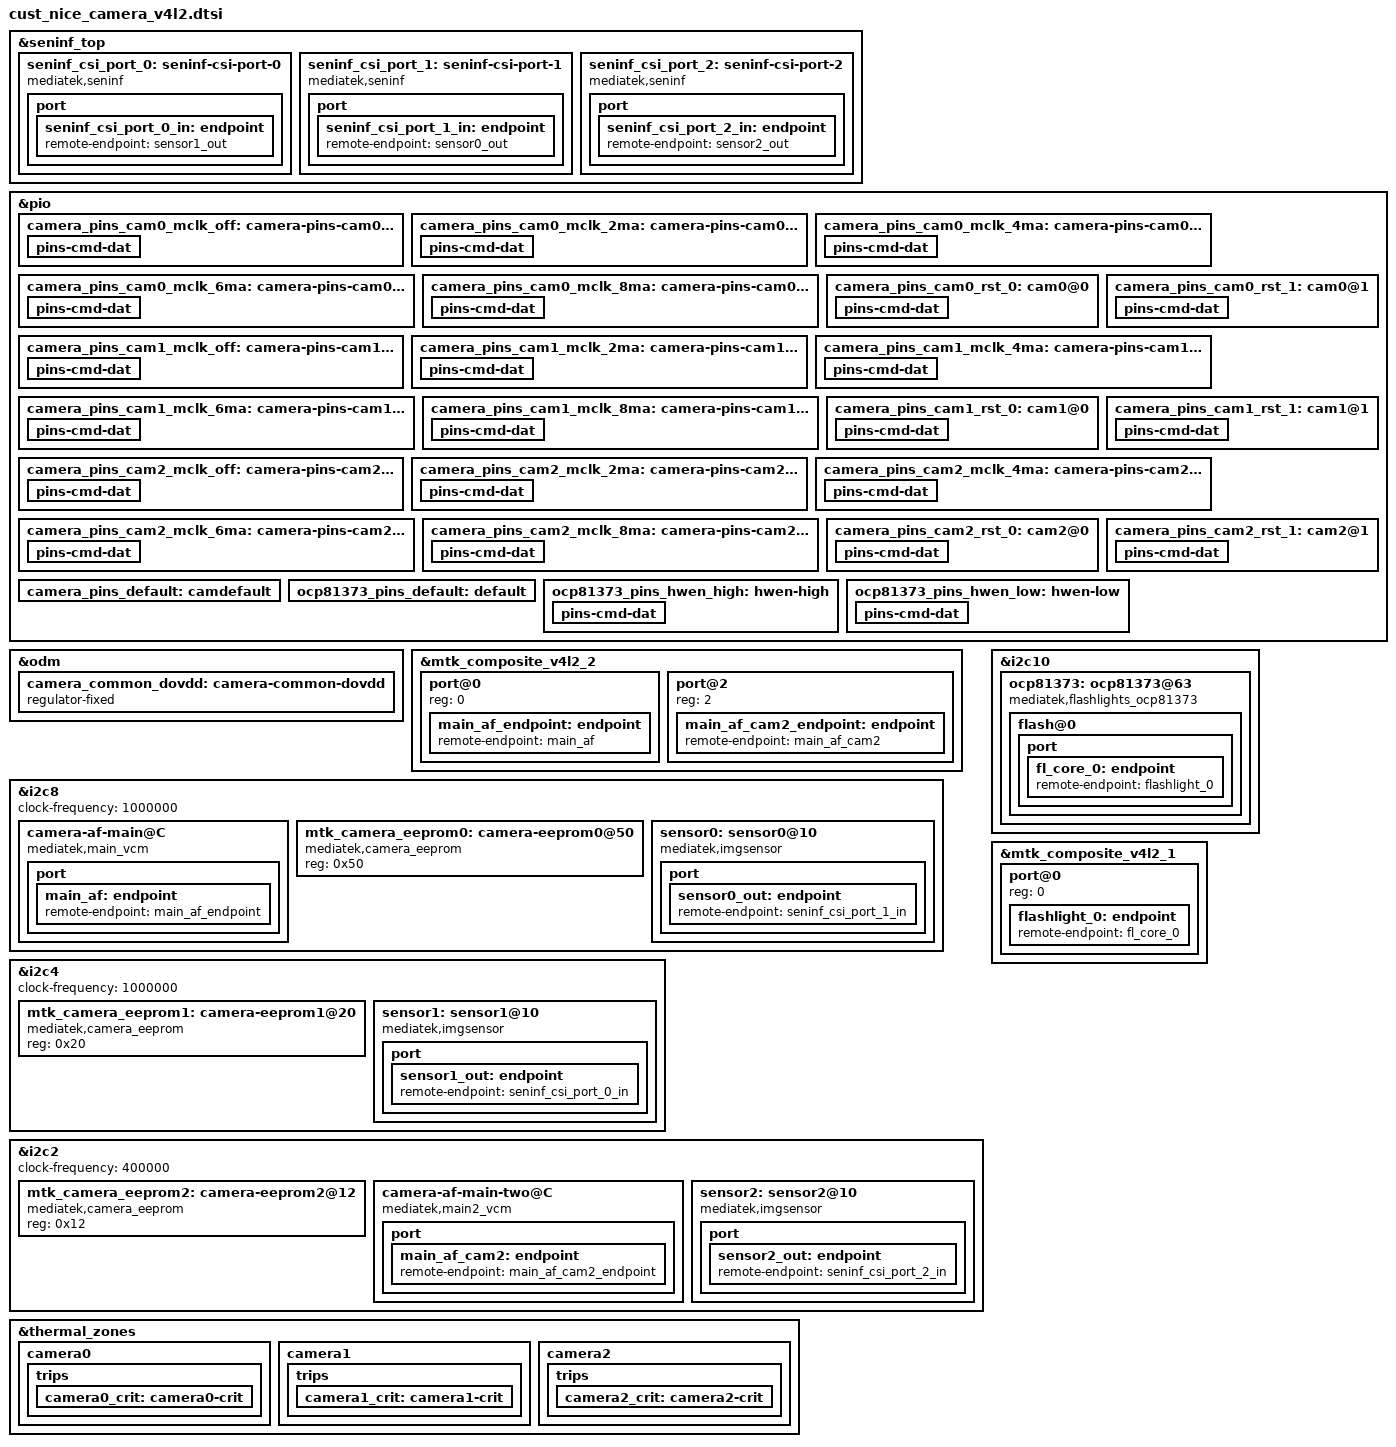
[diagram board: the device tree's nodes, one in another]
// SPDX-License-Identifier: GPL-2.0
/* Copyright (c) 2020 MediaTek Inc. */
#include <dt-bindings/clock/mt6878-clk.h>

&seninf_top {
    seninf_csi_port_0: seninf-csi-port-0 {
        compatible = "mediatek,seninf";
        csi-port = "0";
        dphy-settle-delay-dt = <17>;
        nvmem-cells = <&csi_efuse0>;
        nvmem-cell-names = "rg_csi";
        port {
            seninf_csi_port_0_in: endpoint {
                remote-endpoint = <&sensor1_out>;
            };
        };
    };

    seninf_csi_port_1: seninf-csi-port-1 {
        compatible = "mediatek,seninf";
        csi-port = "1";
        hs-trail-parameter = <0x20>;
        nvmem-cells = <&csi_efuse1>;
        nvmem-cell-names = "rg_csi";
        port {
            seninf_csi_port_1_in: endpoint {
                remote-endpoint = <&sensor0_out>;
            };
        };
    };

    seninf_csi_port_2: seninf-csi-port-2 {
        compatible = "mediatek,seninf";
        csi-port = "2";
        hs-trail-parameter = <0x20>;
        nvmem-cells = <&csi_efuse2>;
        nvmem-cell-names = "rg_csi";
        port {
            seninf_csi_port_2_in: endpoint {
                remote-endpoint = <&sensor2_out>;
            };
        };
    };
};


/* CAMERA GPIO fixed to regulator */

&pio {
    camera_pins_cam0_mclk_off: camera-pins-cam0-mclk-off {
        pins-cmd-dat {
            pinmux = <PINMUX_GPIO94__FUNC_GPIO94>;
            drive-strength = <1>;
        };
    };
    camera_pins_cam0_mclk_2ma: camera-pins-cam0-mclk-2ma {
        pins-cmd-dat {
            pinmux = <PINMUX_GPIO94__FUNC_CMMCLK2>;
            drive-strength = <0>;
        };
    };
    camera_pins_cam0_mclk_4ma: camera-pins-cam0-mclk-4ma {
        pins-cmd-dat {
            pinmux = <PINMUX_GPIO94__FUNC_CMMCLK2>;
            drive-strength = <1>;
        };
    };
    camera_pins_cam0_mclk_6ma: camera-pins-cam0-mclk-6ma {
        pins-cmd-dat {
            pinmux = <PINMUX_GPIO94__FUNC_CMMCLK2>;
            drive-strength = <2>;
        };
    };
    camera_pins_cam0_mclk_8ma: camera-pins-cam0-mclk-8ma {
        pins-cmd-dat {
            pinmux = <PINMUX_GPIO94__FUNC_CMMCLK2>;
            drive-strength = <3>;
        };
    };
    camera_pins_cam0_rst_0: cam0@0 {
        pins-cmd-dat {
            pinmux = <PINMUX_GPIO26__FUNC_GPIO26>;
            slew-rate = <1>;
            output-low;
        };
    };
    camera_pins_cam0_rst_1: cam0@1 {
        pins-cmd-dat {
            pinmux = <PINMUX_GPIO26__FUNC_GPIO26>;
            slew-rate = <1>;
            output-high;
        };
    };

    camera_pins_cam1_mclk_off: camera-pins-cam1-mclk-off {
        pins-cmd-dat {
            pinmux = <PINMUX_GPIO96__FUNC_GPIO96>;
            drive-strength = <1>;
        };
    };
    camera_pins_cam1_mclk_2ma: camera-pins-cam1-mclk-2ma {
        pins-cmd-dat {
            pinmux = <PINMUX_GPIO96__FUNC_CMMCLK4>;
            drive-strength = <0>;
        };
    };
    camera_pins_cam1_mclk_4ma: camera-pins-cam1-mclk-4ma {
        pins-cmd-dat {
            pinmux = <PINMUX_GPIO96__FUNC_CMMCLK4>;
            drive-strength = <1>;
        };
    };
    camera_pins_cam1_mclk_6ma: camera-pins-cam1-mclk-6ma {
        pins-cmd-dat {
            pinmux = <PINMUX_GPIO96__FUNC_CMMCLK4>;
            drive-strength = <2>;
        };
    };
    camera_pins_cam1_mclk_8ma: camera-pins-cam1-mclk-8ma {
        pins-cmd-dat {
            pinmux = <PINMUX_GPIO96__FUNC_CMMCLK4>;
            drive-strength = <3>;
        };
    };
    camera_pins_cam1_rst_0: cam1@0 {
        pins-cmd-dat {
            pinmux = <PINMUX_GPIO24__FUNC_GPIO24>;
            slew-rate = <1>;
            output-low;
        };
    };
    camera_pins_cam1_rst_1: cam1@1 {
        pins-cmd-dat {
            pinmux = <PINMUX_GPIO24__FUNC_GPIO24>;
            slew-rate = <1>;
            output-high;
        };
    };
    camera_pins_cam2_mclk_off: camera-pins-cam2-mclk-off {
        pins-cmd-dat {
            pinmux = <PINMUX_GPIO95__FUNC_GPIO95>;
            drive-strength = <1>;
        };
    };
    camera_pins_cam2_mclk_2ma: camera-pins-cam2-mclk-2ma {
        pins-cmd-dat {
            pinmux = <PINMUX_GPIO95__FUNC_CMMCLK3>;
            drive-strength = <0>;
        };
    };
    camera_pins_cam2_mclk_4ma: camera-pins-cam2-mclk-4ma {
        pins-cmd-dat {
            pinmux = <PINMUX_GPIO95__FUNC_CMMCLK3>;
            drive-strength = <1>;
        };
    };
    camera_pins_cam2_mclk_6ma: camera-pins-cam2-mclk-6ma {
        pins-cmd-dat {
            pinmux = <PINMUX_GPIO95__FUNC_CMMCLK3>;
            drive-strength = <2>;
        };
    };
    camera_pins_cam2_mclk_8ma: camera-pins-cam2-mclk-8ma {
        pins-cmd-dat {
            pinmux = <PINMUX_GPIO95__FUNC_CMMCLK3>;
            drive-strength = <3>;
        };
    };
    camera_pins_cam2_rst_0: cam2@0 {
        pins-cmd-dat {
            pinmux = <PINMUX_GPIO27__FUNC_GPIO27>;
            slew-rate = <1>;
            output-low;
        };
    };
    camera_pins_cam2_rst_1: cam2@1 {
        pins-cmd-dat {
            pinmux = <PINMUX_GPIO27__FUNC_GPIO27>;
            slew-rate = <1>;
            output-high;
        };
    };

    //add for main ois -
    camera_pins_default: camdefault {
    };
};
/* CAMERA GPIO end */

&odm {
        camera_common_dovdd: camera-common-dovdd {
                compatible = "regulator-fixed";
                regulator-name = "camera-common-dovdd";
                regulator-min-microvolt = <1800000>;
                regulator-max-microvolt = <1800000>;
                enable-active-high;
                vin-supply = <&mt6363_vio18>;
        };
};

&mtk_composite_v4l2_2 {
    #address-cells = <1>;
    #size-cells = <0>;
    port@0 {
        reg = <0>;
        main_af_endpoint: endpoint {
            remote-endpoint = <&main_af>;
        };
    };
    port@2 {
        reg = <2>;
        main_af_cam2_endpoint: endpoint {
            remote-endpoint = <&main_af_cam2>;
        };
    };
};

&i2c8 {
    status = "okay";
    clock-frequency = <1000000>;
    camera-af-main@C {
        compatible = "mediatek,main_vcm";
        reg = <0xC>;
        vin-supply = <&mt6369_vio28>;
        port {
            main_af: endpoint {
                remote-endpoint = <&main_af_endpoint>;
            };
        };
    };

    mtk_camera_eeprom0:camera-eeprom0@50 {
        compatible = "mediatek,camera_eeprom";
        reg = <0x50>;
        status = "okay";
    };

    sensor0: sensor0@10 {
        compatible = "mediatek,imgsensor";
        sensor-names = "mot_nice_imx882_mipi_raw";
        reg = <0x10>;

        #thermal-sensor-cells = <0>;

        pinctrl-names = "mclk_off",
                "mclk_2mA",
                "mclk_4mA",
                "mclk_6mA",
                "mclk_8mA",
                "rst_low",
                "rst_high";

        pinctrl-0 = <&camera_pins_cam0_mclk_off>;
        pinctrl-1 = <&camera_pins_cam0_mclk_2ma>;
        pinctrl-2 = <&camera_pins_cam0_mclk_4ma>;
        pinctrl-3 = <&camera_pins_cam0_mclk_6ma>;
        pinctrl-4 = <&camera_pins_cam0_mclk_8ma>;
        pinctrl-5 = <&camera_pins_cam0_rst_0>;
        pinctrl-6 = <&camera_pins_cam0_rst_1>;
        avdd-supply = <&et5904_ldo3>;
        dvdd-supply = <&et5904_ldo1>;

        dovdd-supply = <&camera_common_dovdd>;

        clocks = <&topckgen_clk CLK_TOP_UVPLL192M_D32>,
            <&topckgen_clk CLK_TOP_UVPLL192M_D16>,
            <&topckgen_clk CLK_TOP_OSC_D20>,
            <&topckgen_clk CLK_TOP_UVPLL192M_D10>,
            <&topckgen_clk CLK_TOP_UVPLL192M_D8>,
            <&topckgen_clk CLK_TOP_TCK_26M_MX9>,
            <&topckgen_clk CLK_TOP_UNIVPLL_D6_D8>,
            <&topckgen_clk CLK_TOP_CAMTG3_SEL>;
        clock-names = "6", "12", "13", "19.2", "24", "26", "52", "mclk";

        status = "okay";
        port {
            sensor0_out: endpoint {
                remote-endpoint = <&seninf_csi_port_1_in>;
            };
        };
    };
};

&i2c4 {
    status = "okay";
    clock-frequency = <1000000>;

    mtk_camera_eeprom1:camera-eeprom1@20 {
        compatible = "mediatek,camera_eeprom";
        reg = <0x20>;
        status = "okay";
    };

    sensor1: sensor1@10 {
        compatible = "mediatek,imgsensor";
        sensor-names = "mot_nice_gc32e1_mipi_raw";
        reg = <0x10>;

        #thermal-sensor-cells = <0>;

        pinctrl-names = "mclk_off",
                "mclk_2mA",
                "mclk_4mA",
                "mclk_6mA",
                "mclk_8mA",
                "rst_low",
                "rst_high";
        pinctrl-0 = <&camera_pins_cam1_mclk_off>;
        pinctrl-1 = <&camera_pins_cam1_mclk_2ma>;
        pinctrl-2 = <&camera_pins_cam1_mclk_4ma>;
        pinctrl-3 = <&camera_pins_cam1_mclk_6ma>;
        pinctrl-4 = <&camera_pins_cam1_mclk_8ma>;
        pinctrl-5 = <&camera_pins_cam1_rst_0>;
        pinctrl-6 = <&camera_pins_cam1_rst_1>;

        dvdd-supply = <&et5904_ldo2>;
        avdd-supply = <&et5904_ldo4>;
        dovdd-supply = <&camera_common_dovdd>;

        clocks = <&topckgen_clk CLK_TOP_UVPLL192M_D32>,
            <&topckgen_clk CLK_TOP_UVPLL192M_D16>,
            <&topckgen_clk CLK_TOP_OSC_D20>,
            <&topckgen_clk CLK_TOP_UVPLL192M_D10>,
            <&topckgen_clk CLK_TOP_UVPLL192M_D8>,
            <&topckgen_clk CLK_TOP_TCK_26M_MX9>,
            <&topckgen_clk CLK_TOP_UNIVPLL_D6_D8>,
            <&topckgen_clk CLK_TOP_CAMTG5_SEL>;
        clock-names = "6", "12", "13", "19.2", "24", "26", "52", "mclk";

        status = "okay";
        port {
            sensor1_out: endpoint {
                remote-endpoint = <&seninf_csi_port_0_in>;
            };
        };
    };
};

&i2c2 {
    status = "okay";
    clock-frequency = <400000>;

    mtk_camera_eeprom2:camera-eeprom2@12 {
        compatible = "mediatek,camera_eeprom";
        reg = <0x12>;
        status = "okay";
    };

    camera-af-main-two@C {
        compatible = "mediatek,main2_vcm";
        reg = <0xC>;
        vin-supply = <&et59041c_ldo4>;
        port {
            main_af_cam2: endpoint {
                remote-endpoint = <&main_af_cam2_endpoint>;
            };
        };
    };

    sensor2: sensor2@10 {
        compatible = "mediatek,imgsensor";
        sensor-names = "mot_nice_ov08d_mipi_raw";
        reg = <0x10>;

        #thermal-sensor-cells = <0>;

        pinctrl-names = "mclk_off",
                "mclk_2mA",
                "mclk_4mA",
                "mclk_6mA",
                "mclk_8mA",
                "rst_low",
                "rst_high";

        pinctrl-0 = <&camera_pins_cam2_mclk_off>;
        pinctrl-1 = <&camera_pins_cam2_mclk_2ma>;
        pinctrl-2 = <&camera_pins_cam2_mclk_4ma>;
        pinctrl-3 = <&camera_pins_cam2_mclk_6ma>;
        pinctrl-4 = <&camera_pins_cam2_mclk_8ma>;
        pinctrl-5 = <&camera_pins_cam2_rst_0>;
        pinctrl-6 = <&camera_pins_cam2_rst_1>;
        avdd-supply = <&et59041c_ldo3>;
        dvdd-supply = <&et59041c_ldo2>;
        dovdd-supply = <&camera_common_dovdd>;
        afvdd-supply = <&et59041c_ldo4>;
        clocks = <&topckgen_clk CLK_TOP_UVPLL192M_D32>,
            <&topckgen_clk CLK_TOP_UVPLL192M_D16>,
            <&topckgen_clk CLK_TOP_OSC_D20>,
            <&topckgen_clk CLK_TOP_UVPLL192M_D10>,
            <&topckgen_clk CLK_TOP_UVPLL192M_D8>,
            <&topckgen_clk CLK_TOP_TCK_26M_MX9>,
            <&topckgen_clk CLK_TOP_UNIVPLL_D6_D8>,
            <&topckgen_clk CLK_TOP_CAMTG4_SEL>;
        clock-names = "6", "12", "13", "19.2", "24", "26", "52", "mclk";

        status = "okay";
        port {
            sensor2_out: endpoint {
                remote-endpoint = <&seninf_csi_port_2_in>;
            };
        };
    };
};

&thermal_zones {
    camera0: camera0 {
        polling-delay = <0>; /* milliseconds */
        polling-delay-passive = <0>; /* milliseconds */
        thermal-sensors = <&sensor0>;
        trips {
            camera0_crit: camera0-crit {
                temperature = <120000>;
                hysteresis = <2000>;
                type = "passive";
            };
        };
    };
    camera1: camera1 {
        polling-delay = <0>; /* milliseconds */
        polling-delay-passive = <0>; /* milliseconds */
        thermal-sensors = <&sensor1>;
        trips {
            camera1_crit: camera1-crit {
                temperature = <120000>;
                hysteresis = <2000>;
                type = "passive";
            };
        };
    };
    camera2: camera2 {
        polling-delay = <0>; /* milliseconds */
        polling-delay-passive = <0>; /* milliseconds */
        thermal-sensors = <&sensor2>;
        trips {
            camera2_crit: camera2-crit {
                temperature = <120000>;
                hysteresis = <2000>;
                type = "passive";
            };
        };
    };
};

&i2c10 {
    #address-cells = <1>;
    #size-cells = <0>;
    ocp81373:ocp81373@63 {
        compatible = "mediatek,flashlights_ocp81373";
        #address-cells = <1>;
        #size-cells = <0>;
        reg = <0x63>;
        #cooling-cells = <2>;
        pinctrl-names = "default", "hwen-high", "hwen-low";
        pinctrl-0 = <&ocp81373_pins_default>;
        pinctrl-1 = <&ocp81373_pins_hwen_high>;
        pinctrl-2 = <&ocp81373_pins_hwen_low>;
        status = "okay";
        decouple = <1>;
        flash@0{
            reg = <0>;
            type = <0>;
            ct = <0>;
            part = <0>;
            port {
                fl_core_0: endpoint {
                    remote-endpoint = <&flashlight_0>;
                };
            };
        };
    };
};



&pio {
    ocp81373_pins_default: default {
    };

    ocp81373_pins_hwen_high: hwen-high {
        pins-cmd-dat {
            pinmux = <PINMUX_GPIO153__FUNC_GPIO153>;
            slew-rate = <1>;
            output-high;
        };
    };

    ocp81373_pins_hwen_low: hwen-low {
        pins-cmd-dat {
            pinmux = <PINMUX_GPIO153__FUNC_GPIO153>;
            slew-rate = <1>;
            output-low;
        };
    };
};


&mtk_composite_v4l2_1 {
    #address-cells = <1>;
    #size-cells = <0>;
    port@0 {
        reg = <0>;
        flashlight_0: endpoint {
            remote-endpoint = <&fl_core_0>;
        };
    };
};

